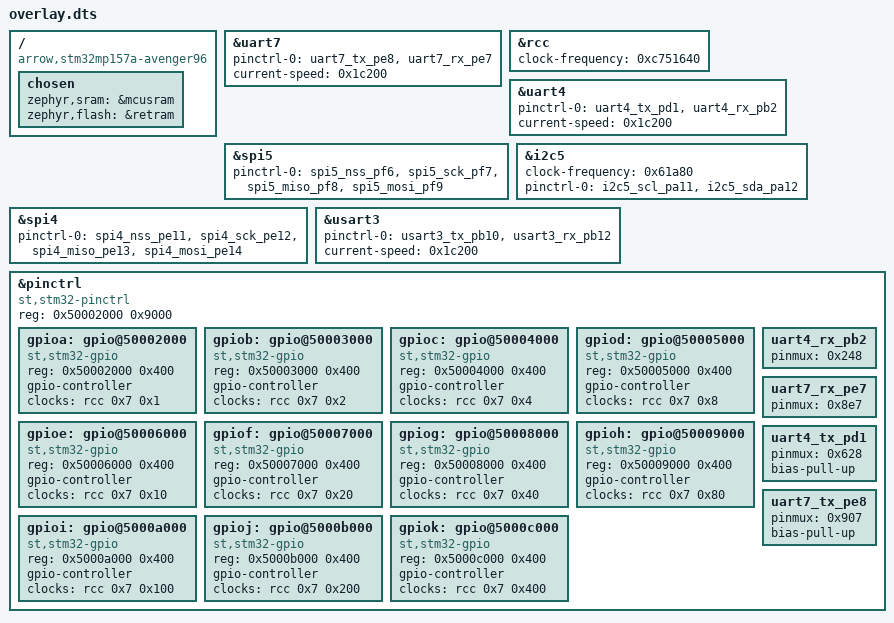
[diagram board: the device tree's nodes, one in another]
/ {
	compatible = "arrow,stm32mp157a-avenger96";
	chosen {
		zephyr,sram = &mcusram;
		zephyr,flash = &retram;
	};
};
&uart7{
	status = "okay";
	pinctrl-0 = < &uart7_tx_pe8 &uart7_rx_pe7 >;
	pinctrl-names = "default";
	current-speed = < 0x1c200 >;
};
&rcc{
	clock-frequency = < 0xc751640 >;
};
&uart4{
	status = "okay";
	pinctrl-0 = < &uart4_tx_pd1 &uart4_rx_pb2 >;
	pinctrl-names = "default";
	current-speed = < 0x1c200 >;
};
&spi5{
	status = "okay";
	pinctrl-0 = < &spi5_nss_pf6 &spi5_sck_pf7 &spi5_miso_pf8 &spi5_mosi_pf9 >;
	pinctrl-names = "default";
};
&i2c5{
	clock-frequency = < 0x61a80 >;
	status = "okay";
	pinctrl-0 = < &i2c5_scl_pa11 &i2c5_sda_pa12 >;
	pinctrl-names = "default";
};
&spi4{
	status = "okay";
	pinctrl-0 = < &spi4_nss_pe11 &spi4_sck_pe12 &spi4_miso_pe13 &spi4_mosi_pe14 >;
	pinctrl-names = "default";
};
&usart3{
	status = "okay";
	pinctrl-0 = < &usart3_tx_pb10 &usart3_rx_pb12 >;
	pinctrl-names = "default";
	current-speed = < 0x1c200 >;
};
&pinctrl{
	compatible = "st,stm32-pinctrl";
	reg = < 0x50002000 0x9000 >;
	#address-cells = < 0x1 >;
	#size-cells = < 0x1 >;
	gpioa: gpio@50002000 {
		compatible = "st,stm32-gpio";
		reg = < 0x50002000 0x400 >;
		gpio-controller;
		#gpio-cells = < 0x2 >;
		clocks = < &rcc 0x7 0x1 >;
	};
	gpiob: gpio@50003000 {
		compatible = "st,stm32-gpio";
		reg = < 0x50003000 0x400 >;
		gpio-controller;
		#gpio-cells = < 0x2 >;
		clocks = < &rcc 0x7 0x2 >;
	};
	gpioc: gpio@50004000 {
		compatible = "st,stm32-gpio";
		reg = < 0x50004000 0x400 >;
		gpio-controller;
		#gpio-cells = < 0x2 >;
		clocks = < &rcc 0x7 0x4 >;
	};
	gpiod: gpio@50005000 {
		compatible = "st,stm32-gpio";
		reg = < 0x50005000 0x400 >;
		gpio-controller;
		#gpio-cells = < 0x2 >;
		clocks = < &rcc 0x7 0x8 >;
	};
	gpioe: gpio@50006000 {
		compatible = "st,stm32-gpio";
		reg = < 0x50006000 0x400 >;
		gpio-controller;
		#gpio-cells = < 0x2 >;
		clocks = < &rcc 0x7 0x10 >;
	};
	gpiof: gpio@50007000 {
		compatible = "st,stm32-gpio";
		reg = < 0x50007000 0x400 >;
		gpio-controller;
		#gpio-cells = < 0x2 >;
		clocks = < &rcc 0x7 0x20 >;
	};
	gpiog: gpio@50008000 {
		compatible = "st,stm32-gpio";
		reg = < 0x50008000 0x400 >;
		gpio-controller;
		#gpio-cells = < 0x2 >;
		clocks = < &rcc 0x7 0x40 >;
	};
	gpioh: gpio@50009000 {
		compatible = "st,stm32-gpio";
		reg = < 0x50009000 0x400 >;
		gpio-controller;
		#gpio-cells = < 0x2 >;
		clocks = < &rcc 0x7 0x80 >;
	};
	gpioi: gpio@5000a000 {
		compatible = "st,stm32-gpio";
		reg = < 0x5000a000 0x400 >;
		gpio-controller;
		#gpio-cells = < 0x2 >;
		clocks = < &rcc 0x7 0x100 >;
	};
	gpioj: gpio@5000b000 {
		compatible = "st,stm32-gpio";
		reg = < 0x5000b000 0x400 >;
		gpio-controller;
		#gpio-cells = < 0x2 >;
		clocks = < &rcc 0x7 0x200 >;
	};
	gpiok: gpio@5000c000 {
		compatible = "st,stm32-gpio";
		reg = < 0x5000c000 0x400 >;
		gpio-controller;
		#gpio-cells = < 0x2 >;
		clocks = < &rcc 0x7 0x400 >;
	};
	uart4_rx_pb2: uart4_rx_pb2 {
		pinmux = < 0x248 >;
	};
	uart7_rx_pe7: uart7_rx_pe7 {
		pinmux = < 0x8e7 >;
	};
	uart4_tx_pd1: uart4_tx_pd1 {
		pinmux = < 0x628 >;
		bias-pull-up;
	};
	uart7_tx_pe8: uart7_tx_pe8 {
		pinmux = < 0x907 >;
		bias-pull-up;
	};
};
